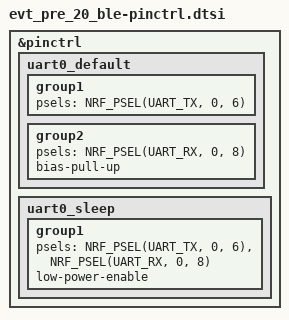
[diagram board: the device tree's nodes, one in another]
/* U11 pad 22 P0.06 = UARTE TX (BLE_RX net), pad 24 P0.08 = UARTE RX (BLE_TX net); no RTS/CTS on Rev.A. */
&pinctrl {
	uart0_default: uart0_default {
		group1 {
			psels = <NRF_PSEL(UART_TX, 0, 6)>;
		};
		group2 {
			psels = <NRF_PSEL(UART_RX, 0, 8)>;
			bias-pull-up;
		};
	};

	uart0_sleep: uart0_sleep {
		group1 {
			psels = <NRF_PSEL(UART_TX, 0, 6)>,
				<NRF_PSEL(UART_RX, 0, 8)>;
			low-power-enable;
		};
	};
};
